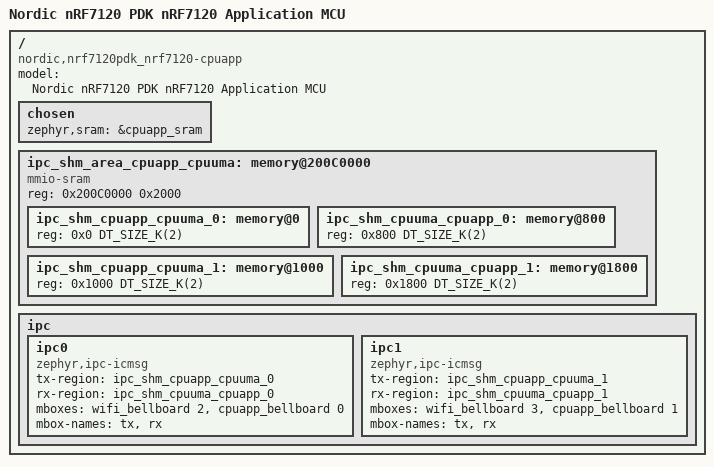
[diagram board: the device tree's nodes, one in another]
/*
 * Copyright (c) 2025 Nordic Semiconductor ASA
 *
 * SPDX-License-Identifier: LicenseRef-Nordic-5-Clause
 */

/dts-v1/;

#include "nrf7120_cpuapp_common.dtsi"

/ {
	compatible = "nordic,nrf7120pdk_nrf7120-cpuapp";
	model = "Nordic nRF7120 PDK nRF7120 Application MCU";

	chosen {
		zephyr,sram = &cpuapp_sram;
	};

	ipc_shm_area_cpuapp_cpuuma: memory@200C0000 {
		compatible = "mmio-sram";
		reg = <0x200C0000 0x2000>;
		ranges = <0x0 0x200C0000 0x2000>;
		#address-cells = <1>;
		#size-cells = <1>;
		status = "okay";

		ipc_shm_cpuapp_cpuuma_0: memory@0 {
			reg = <0x0 DT_SIZE_K(2)>;
		};

		ipc_shm_cpuuma_cpuapp_0: memory@800 {
			reg = <0x800 DT_SIZE_K(2)>;
		};

		ipc_shm_cpuapp_cpuuma_1: memory@1000 {
			reg = <0x1000 DT_SIZE_K(2)>;
		};

		ipc_shm_cpuuma_cpuapp_1: memory@1800 {
			reg = <0x1800 DT_SIZE_K(2)>;
		};
	};

	ipc {
		ipc0: ipc0 {
			compatible = "zephyr,ipc-icmsg";
			// TODO: Need shared memory between APP-WIFI
			tx-region = <&ipc_shm_cpuapp_cpuuma_0>;
			// TODO: Need shared memory between APP-WIFI
			rx-region = <&ipc_shm_cpuuma_cpuapp_0>;
			mboxes = <&wifi_bellboard 2>,
				<&cpuapp_bellboard  0>;
			mbox-names = "tx", "rx";
			status = "okay";
		};

		ipc1: ipc1 {
			compatible = "zephyr,ipc-icmsg";
			// TODO: Need shared memory between APP-WIFI
			tx-region = <&ipc_shm_cpuapp_cpuuma_1>;
			// TODO: Need shared memory between APP-WIFI
			rx-region = <&ipc_shm_cpuuma_cpuapp_1>;
			mboxes = <&wifi_bellboard 3>,
				<&cpuapp_bellboard  1>;
			mbox-names = "tx", "rx";
			status = "okay";
		};
	};
};
